# STM32MP25_CM33 register map
File version: 1.3
CPU: CM33 r0p1, little endian, MPU, FPU, vendor SysTick, 8 interrupt priority bits
Registers are 32-bit, read-write, reset 0x0 unless marked. A register's access mark holds for its fields unless they carry their own. Offsets are from the block's base; [hi:lo] are bit positions; {n}, {i} and the like mark numbered series; 'fields as' and 'values as' point back to an identical list.

## GPIOZ — Control of ioport Z
Base 0x46200000
Same registers: GPIOZ_S 0x56200000
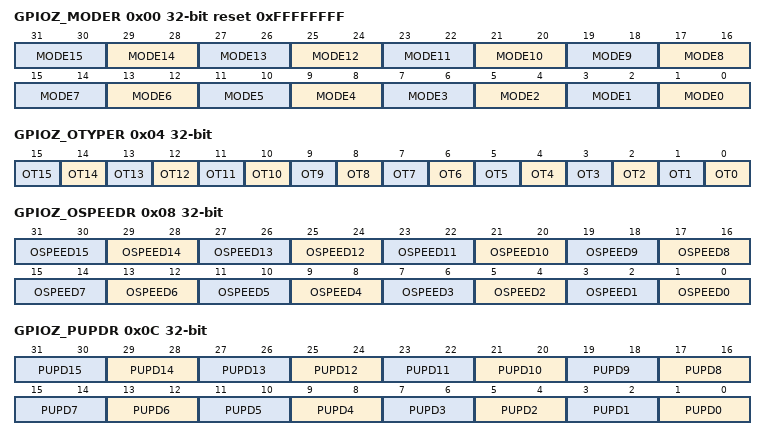
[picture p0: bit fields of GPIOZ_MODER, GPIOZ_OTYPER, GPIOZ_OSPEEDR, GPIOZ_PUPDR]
0x00 GPIOZ_MODER reset 0xFFFFFFFF — GPIO port Z mode register
  [all] fields
    0=General-purpose input mode; 1=General-purpose output mode; 2=Alternate-function mode (refer to device datasheet for available options); 3=Analog mode (reset state)
  [2n+1:2n] MODE{n} (n=0..15) — Port x configuration I/O pin y
0x04 GPIOZ_OTYPER — GPIO port Z output type register
  [all] fields
    0=Output push-pull (reset state); 1=Output open-drain
  [n] OT{n} (n=0..15) — Port x configuration I/O pin y
0x08 GPIOZ_OSPEEDR — GPIO port Z output speed register
  [all] fields
    0=Low speed; 1=Medium speed; 2=High speed; 3=Very-high speed
  [2n+1:2n] OSPEED{n} (n=0..15) — Port x configuration I/O pin y
0x0C GPIOZ_PUPDR — GPIO port pull-up/pull-down register
  [all] fields
    0=No pull-up, pull-down; 1=Pull-up; 2=Pull-down
  [2n+1:2n] PUPD{n} (n=0..15) — Port x configuration I/O pin y
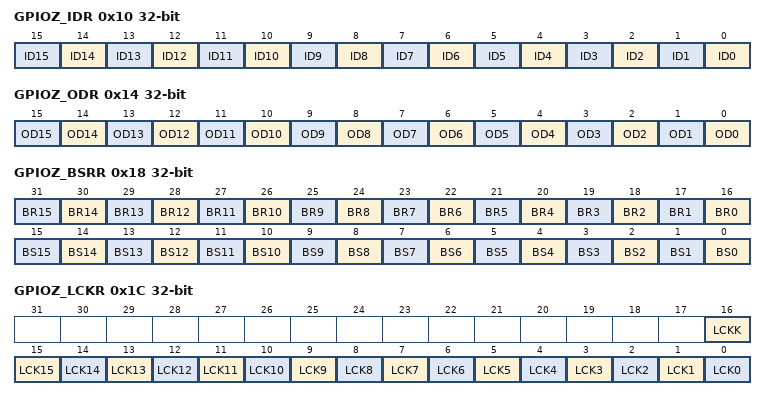
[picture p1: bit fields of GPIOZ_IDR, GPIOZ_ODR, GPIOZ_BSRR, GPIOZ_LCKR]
0x10 GPIOZ_IDR ro (reset mask 0xFFFF0000) — GPIO port Z input data register
  [n] ID{n} (n=0..15) — Port x input data I/O pin y
0x14 GPIOZ_ODR — GPIO port Z output data register
  [n] OD{n} (n=0..15) — Port x output data I/O pin y
0x18 GPIOZ_BSRR wo — GPIO port Z bit set/reset register
  [n+16] BR{n} (n=0..15) — Port x reset I/O pin y
    0=No action on the corresponding ODx bit; 1=Resets the corresponding ODx bit
  [n] BS{n} (n=0..15) — Port x set I/O pin y
    0=No action on the corresponding ODx bit; 1=Sets the corresponding ODx bit
0x1C GPIOZ_LCKR — GPIO port Z configuration lock register
  [16] LCKK — Lock key
    0=Port configuration lock key not active; 1=Port configuration lock key active
  [n] LCK{n} (n=0..15) — Port x lock I/O pin y
    0=Port configuration not locked; 1=Port configuration locked
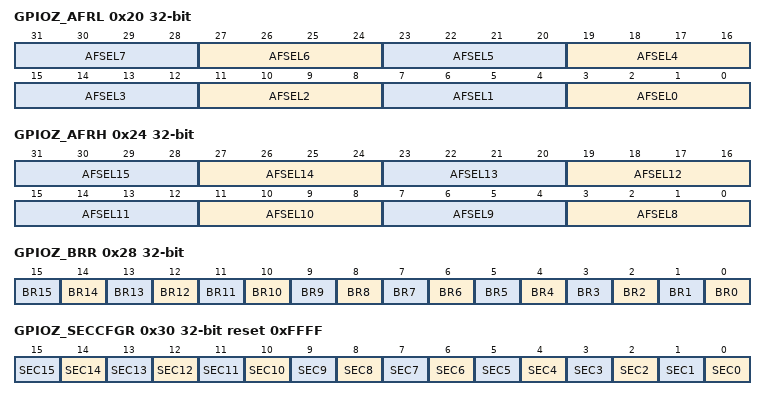
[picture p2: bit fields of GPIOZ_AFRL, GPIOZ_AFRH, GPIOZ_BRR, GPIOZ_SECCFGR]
0x20 GPIOZ_AFRL — GPIO port Z alternate function low register
  [all] fields
    {v}=AF{v} (v=0..15)
  [4n+3:4n] AFSEL{n} (n=0..7) — Alternate function selection for port x I/O pin y
0x24 GPIOZ_AFRH — GPIO port Z alternate function high register
  [4n-29:4n-32] AFSEL{n} (n=8..15) — Alternate function selection for port x I/O pin y
0x28 GPIOZ_BRR wo — GPIO port Z bit reset register
  [all] fields
    0=No action on the corresponding ODx bit; 1=Reset the corresponding ODx bit
  [n] BR{n} (n=0..15) — Port x reset I/O pin y
0x30 GPIOZ_SECCFGR reset 0xFFFF — GPIO port Z secure configuration register
  [all] fields
    0=The I/O pin y is non-secure; 1=The I/O pin y is secure
  [n] SEC{n} (n=0..15) — I/O pin y of Port x security configuration
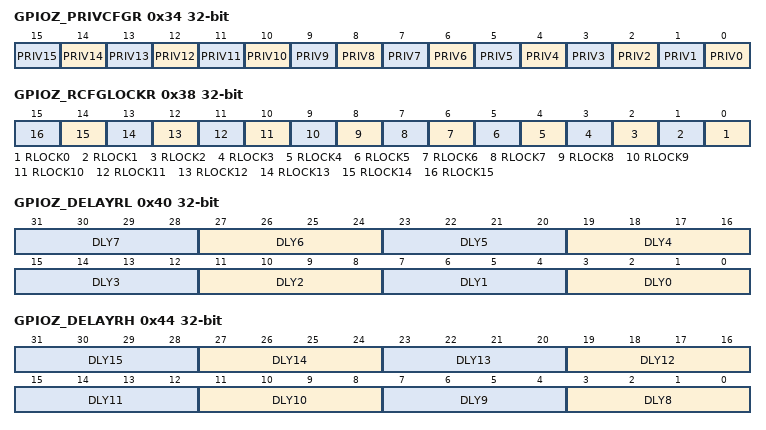
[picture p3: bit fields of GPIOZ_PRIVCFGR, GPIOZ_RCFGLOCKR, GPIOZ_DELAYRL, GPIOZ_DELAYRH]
0x34 GPIOZ_PRIVCFGR — GPIO port Z privileged configuration register
  [all] fields
    0=The I/O pin y is unprivileged; 1=The I/O pin y is privileged only
  [n] PRIV{n} (n=0..15) — I/O pin y of port x privilege configuration
0x38 GPIOZ_RCFGLOCKR — GPIO port Z resource configuration lock register
  [all] fields
    0=Bits SECy in GPIOx_SECCFGR and PRIVy in GPIOx_PRIVCFGR are writable; 1=Writes to bits SECy in GPIOx_SECCFGR and PRIVy in GPIOx_PRIVCFGR are ignored
  [n] RLOCK{n} (n=0..15) — I/O pin y of port x resource lock
0x40 GPIOZ_DELAYRL — GPIO port Z delay low register
  [all] fields
    0=no delay; 1=delay 0; 2=delay 0; 3=delay 0; {v}=delay 1 (v=4..7); {v}=delay 2 (v=8..11); 12=delay 3; 13=delay 3
  [4n+3:4n] DLY{n} (n=0..7) — Port x IO pin y delay setup
0x44 GPIOZ_DELAYRH — GPIO port Z delay high register
  [4n-29:4n-32] DLY{n} (n=8..15) — Port x IO pin y delay setup
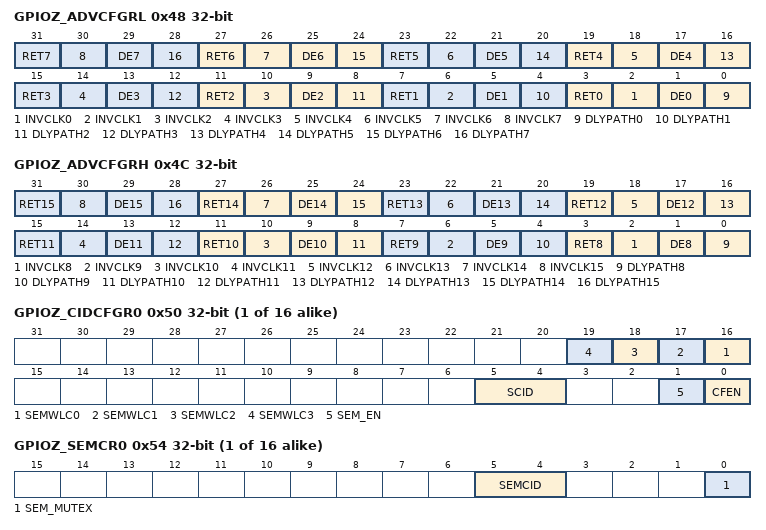
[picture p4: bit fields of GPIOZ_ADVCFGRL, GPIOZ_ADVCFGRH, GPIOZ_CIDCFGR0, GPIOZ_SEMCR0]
0x48 GPIOZ_ADVCFGRL — GPIO port Z advanced configuration low register
  [4n+3] RET{n} (n=0..7) — Data retime selection y (y=7to0)
    0=Input and output data are not synchronized or retimed on clock edges; 1=Input and output data are retimed to either rising or falling clock edge depending on value of INVCLKy
  [4n+2] INVCLK{n} (n=0..7) — Clock inversion selection y (y=7to0)
    0=I/O clocks are not inverted; 1=I/O clocks are inverted
  [4n+1] DE{n} (n=0..7) — Input/Output data double edge selection y (y=7to0)
    0=Input and output data is single-edge (changing on rising or falling clock edge, but not both); 1=Input and output data is double-edge (changing on both rising and falling clock edges)
  [4n] DLYPATH{n} (n=0..7) — Controls which path contains the configurable delay, input or output y (y=7to0)
    0=Delay is switched into the output path, while the input path is set as pass through; 1=Delay is switched into the input path, while the output path is set as pass through
0x4C GPIOZ_ADVCFGRH — GPIO port Z advanced configuration high register
  [4n-29] RET{n} (n=8..15) — Data retime selection y (y=15to8)
    values as GPIOZ_ADVCFGRL.RET0
  [4n-30] INVCLK{n} (n=8..15) — Clock inversion selection y (y=15to8)
    0=I/O clocks are not inverted; 1=I/O clocks are inverted
  [4n-31] DE{n} (n=8..15) — Input/Output data double edge selection y (y=15to8)
    values as GPIOZ_ADVCFGRL.DE0
  [4n-32] DLYPATH{n} (n=8..15) — Controls which path contains the configurable delay, input or output y (y=15to8)
    values as GPIOZ_ADVCFGRL.DLYPATH0
{0x50+8i} GPIOZ_CIDCFGR{i} (i=0..15) — GPIO port Z CID configuration register for I/O pin {i}
  [n+16] SEMWLC{n} (n=0..3) — Semaphore white list for compartment z
    0=Application running in compartment z cannot get access to the I/O pin y throughsemaphore SEM_MUTEX; 1=Application running in compartment z can get access to the I/O pin y throughsemaphoreSEM_MUTEX
  [5:4] SCID — Static CID
  [1] SEM_EN — Semaphore enable
    0=Access to I/O pin y is granted only if CID of the access equals to SCID; 1=Access to I/O pin y is granted only if SEM_MUTEX=1 and CID of the access equals toSEMCID in GPIOx_SEMCR
  [0] CFEN — CID filtering enable
    0=Compartment-based filtering defined in GPIOx_CIDCFGR, and optionally GPIOx_SEMCRis disabled for I/O pin y; 1=Compartment-based filtering defined in GPIOx_CIDCFGR, and optionally GPIOx_SEMCRis enabled for I/O pin y
{0x54+8i} GPIOZ_SEMCR{i} (i=0..15) — GPIO port Z semaphore control register for I/O pin {i}
  [5:4] SEMCID ro — Semaphore current CID
  [0] SEM_MUTEX — Semaphore mutex
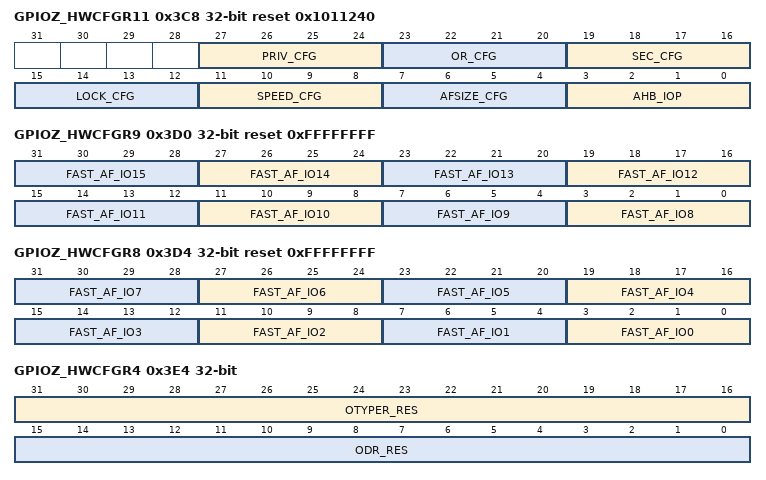
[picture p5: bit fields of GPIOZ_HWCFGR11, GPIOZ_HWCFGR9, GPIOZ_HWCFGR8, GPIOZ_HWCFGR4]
0x3C8 GPIOZ_HWCFGR11 ro reset 0x1011240 — GPIO port Z hardware configuration register 11
  [27:24] PRIV_CFG — Privilege mechanism activation
    0=Non active; 1=Active
  [23:20] OR_CFG — Option register configuration
    0=Non active; 1=Active
  [19:16] SEC_CFG — Security activation
    0=Non active; 1=Active
  [15:12] LOCK_CFG — Lock mechanism activation
    0=Non active; 1=Active
  [11:8] SPEED_CFG — Number of speed lines for each I/O
    1=One line
  [7:4] AFSIZE_CFG — Number of AF available for each I/O
    1=One AF/IO
  [3:0] AHB_IOP — Bus interface selection
    0=AHB; 1=IOP
0x3CC GPIOZ_HWCFGR10 ro reset 0xFFFF — GPIO port Z hardware configuration register 10
  [15:0] EN_IO — Presence granularity, each bit indicate the I/O presence
    0=I/O not present; 1=I/O present
0x3D0 GPIOZ_HWCFGR9 ro reset 0xFFFFFFFF — GPIO port Z hardware configuration register 9
  [4n-29:4n-32] FAST_AF_IO{n} (n=8..15) — Indicate which is the fastest AF for I/O{n} (0 to F)
0x3D4 GPIOZ_HWCFGR8 ro reset 0xFFFFFFFF — GPIO port Z hardware configuration register 8
  [4n+3:4n] FAST_AF_IO{n} (n=0..7) — Indicate which is the fastest AF for I/O{n} (0 to F)
0x3D8 GPIOZ_HWCFGR7 ro reset 0xFFFFFFFF — GPIO port Z hardware configuration register 7
  [31:0] MODER_RES — MODER register reset value
0x3DC GPIOZ_HWCFGR6 ro — GPIO port Z hardware configuration register 6
  [31:0] PUPDR_RES — Pull-up/pull-down register reset value
0x3E0 GPIOZ_HWCFGR5 ro — GPIO port Z hardware configuration register 5
  [31:0] OSPEED_RES — OSPEED register reset value
0x3E4 GPIOZ_HWCFGR4 ro — GPIO port Z hardware configuration register 4
  [31:16] OTYPER_RES — Output type register reset value
  [15:0] ODR_RES — Output data register reset value
0x3E8 GPIOZ_HWCFGR3 ro — GPIO port Z hardware configuration register 3
  [31:0] AFRL_RES — AF register low reset value
0x3EC GPIOZ_HWCFGR2 ro — GPIO port Z hardware configuration register 2
  [31:0] AFRH_RES — AF register high reset value
0x3F0 GPIOZ_HWCFGR1 ro — GPIO port Z hardware configuration register 1
  [15:0] OR_RES — Option register reset value
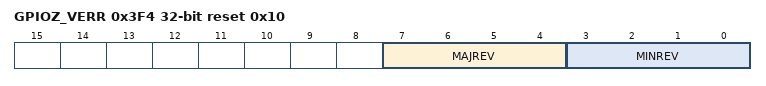
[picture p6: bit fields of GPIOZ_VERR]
0x3F4 GPIOZ_VERR ro reset 0x10 — GPIO port Z version register
  [7:4] MAJREV — GPIO major revision
  [3:0] MINREV — GPIO minor revision
0x3F8 GPIOZ_IPIDR ro reset 0xF0004 — GPIO port Z identification register
  [31:0] IPID — GPIO identifier
0x3FC GPIOZ_SIDR ro reset 0xA3C5DD01 — GPIO port Z size identification register
  [31:0] SID — Size identifier
